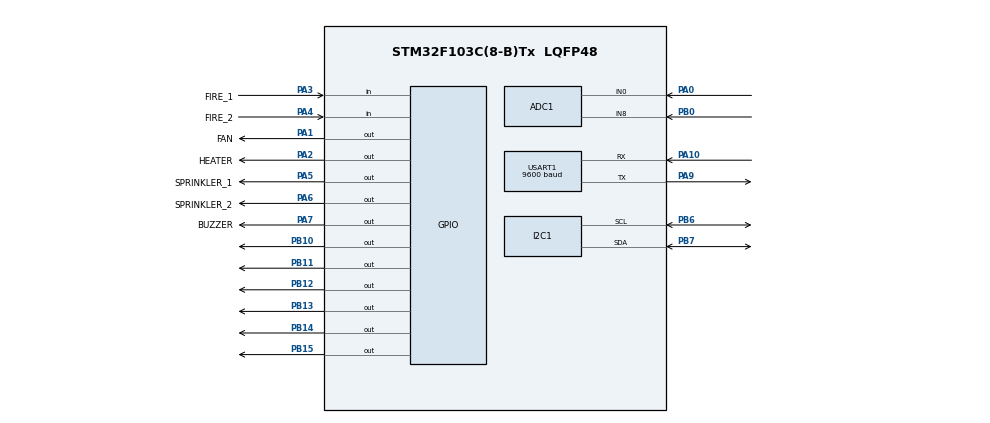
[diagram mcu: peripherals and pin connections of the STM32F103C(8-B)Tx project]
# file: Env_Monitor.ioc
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ADC1.Channel-0\#ChannelRegularConversion=ADC_CHANNEL_0
ADC1.NbrOfConversionFlag=1
ADC1.Rank-0\#ChannelRegularConversion=1
ADC1.SamplingTime-0\#ChannelRegularConversion=ADC_SAMPLETIME_1CYCLE_5
ADC1.master=1
Mcu.Family=STM32F1
Mcu.Name=STM32F103C(8-B)Tx
Mcu.Package=LQFP48
NVIC.PriorityGroup=NVIC_PRIORITYGROUP_4
NVIC.USART1_IRQn=true\:0\:0\:false\:false\:true\:true\:true\:true
PA0-WKUP.Signal=ADCx_IN0
PA1.GPIO_Label=FAN
PA1.Signal=GPIO_Output
PA10.Mode=Asynchronous
PA10.Signal=USART1_RX
PA2.GPIO_Label=HEATER
PA2.Signal=GPIO_Output
PA3.GPIO_Label=FIRE_1
PA3.GPIO_PuPd=GPIO_PULLDOWN
PA3.Signal=GPIO_Input
PA4.GPIO_Label=FIRE_2
PA4.GPIO_PuPd=GPIO_PULLDOWN
PA4.Signal=GPIO_Input
PA5.GPIO_Label=SPRINKLER_1
PA5.Signal=GPIO_Output
PA6.GPIO_Label=SPRINKLER_2
PA6.Signal=GPIO_Output
PA7.GPIO_Label=BUZZER
PA7.Signal=GPIO_Output
PA9.Mode=Asynchronous
PA9.Signal=USART1_TX
PB0.Signal=ADCx_IN8
PB10.Signal=GPIO_Output
PB11.Signal=GPIO_Output
PB12.Signal=GPIO_Output
PB13.Signal=GPIO_Output
PB14.Signal=GPIO_Output
PB15.Signal=GPIO_Output
PB6.Mode=I2C
PB6.Signal=I2C1_SCL
PB7.Mode=I2C
PB7.Signal=I2C1_SDA
ProjectManager.HeapSize=0x200
ProjectManager.StackSize=0x400
ProjectManager.TargetToolchain=STM32CubeIDE
RCC.APB1Freq_Value=8000000
RCC.APB2Freq_Value=8000000
SH.ADCx_IN0.0=ADC1_IN0,IN0
SH.ADCx_IN8.0=ADC1_IN8,IN8
USART1.BaudRate=9600
USART1.VirtualMode=VM_ASYNC
VP_RTC_VS_RTC_Activate.Mode=RTC_Enabled
VP_RTC_VS_RTC_Calendar.Mode=RTC_Calendar
VP_SYS_VS_ND.Mode=No_Debug
board=custom

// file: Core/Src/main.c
/* USER CODE BEGIN Header */
/**
  ******************************************************************************
  * @file           : main.c
  * @brief          : Main program body
  ******************************************************************************
  * @attention
  *
  * Copyright (c) 2026 STMicroelectronics.
  * All rights reserved.
  *
  * This software is licensed under terms that can be found in the LICENSE file
  * in the root directory of this software component.
  * If no LICENSE file comes with this software, it is provided AS-IS.
  *
  ******************************************************************************
  */
/* USER CODE END Header */
#include "main.h"
#include "adc.h"
#include "i2c.h"
#include "rtc.h"
#include "usart.h"
#include "gpio.h"

/* USER CODE BEGIN Includes */
#include "environment.h"
/* USER CODE END Includes */

/* USER CODE BEGIN PD */
//void Stream_System_Telemetry(void) {
//    char tx_packet[256];
//    RTC_TimeTypeDef sTime = {0};
//    RTC_DateTypeDef sDate = {0};
//
//    HAL_RTC_GetTime(&hrtc, &sTime, RTC_FORMAT_BIN);
//    HAL_RTC_GetDate(&hrtc, &sDate, RTC_FORMAT_BIN);
//
//    float cur_t = (total_samples_collected > 0) ? temp_history[(buffer_index == 0 ? MOVING_AVG_SAMPLES : buffer_index) - 1] : 0.0f; // Derived from core history logic
//    float avg_t = Get_Average_Temperature();
//    char fire_msg[15];
//    uint8_t fire_triggered = (HAL_GPIO_ReadPin(GPIOA, GPIO_PIN_3) == GPIO_PIN_SET) ||
//                             (HAL_GPIO_ReadPin(GPIOA, GPIO_PIN_4) == GPIO_PIN_SET);
//
//    snprintf(tx_packet, sizeof(tx_packet),
//             "@TIME=%02d:%02d:%02d|DATE=%02d-%02d-%02d|CUR=%.1f|AVG=%.1f|FIRE=%d|LOCK=%d|TARG=%.1f\n",
//             sTime.Hours, sTime.Minutes, sTime.Seconds,
//             sDate.Year, sDate.Month, sDate.Date,
//             cur_t, avg_t, fire_triggered, is_system_locked, target_temp);
//
//    HAL_UART_Transmit(&huart1, (uint8_t*)tx_packet, strlen(tx_packet), 200);
//}
/* USER CODE END PD */

/* USER CODE BEGIN PV */
extern RTC_HandleTypeDef hrtc;
uint8_t rx_char;
/* USER CODE END PV */

void SystemClock_Config(void);

int main(void)
{

  /* MCU Configuration--------------------------------------------------------*/

  /* Reset of all peripherals, Initializes the Flash interface and the Systick. */
  HAL_Init();

  /* Configure the system clock */
  SystemClock_Config();

  /* Initialize all configured peripherals */
  MX_GPIO_Init();
  MX_ADC1_Init();
  MX_USART1_UART_Init();
  MX_RTC_Init();
  MX_I2C1_Init();
  /* USER CODE BEGIN 2 */
  ENV_Init(&hadc1, &huart1, &hrtc);
  HAL_UART_Receive_IT(&huart1, &rx_char, 1);
  /* USER CODE END 2 */

  /* Infinite loop */
  /* USER CODE BEGIN WHILE */

  uint32_t last_execution_time = 0;
  while (1)
  {
    /* USER CODE END WHILE */

    /* USER CODE BEGIN 3 */
	  uint32_t current_time = HAL_GetTick();
	  if (current_time - last_execution_time >= 1000)
	      {
	          ENV_Task();
	          last_execution_time = current_time;
	      }
	  // Non-Blocking State Machine
//       ENV_Task();
//       HAL_Delay(1500);

  }
  /* USER CODE END 3 */
}

void SystemClock_Config(void)
{
  RCC_OscInitTypeDef RCC_OscInitStruct = {0};
  RCC_ClkInitTypeDef RCC_ClkInitStruct = {0};
  RCC_PeriphCLKInitTypeDef PeriphClkInit = {0};

  /** Initializes the RCC Oscillators according to the specified parameters
  * in the RCC_OscInitTypeDef structure.
  */
  RCC_OscInitStruct.OscillatorType = RCC_OSCILLATORTYPE_HSI|RCC_OSCILLATORTYPE_LSI;
  RCC_OscInitStruct.HSIState = RCC_HSI_ON;
  RCC_OscInitStruct.HSICalibrationValue = RCC_HSICALIBRATION_DEFAULT;
  RCC_OscInitStruct.LSIState = RCC_LSI_ON;
  RCC_OscInitStruct.PLL.PLLState = RCC_PLL_NONE;
  if (HAL_RCC_OscConfig(&RCC_OscInitStruct) != HAL_OK)
  {
    Error_Handler();
  }

  /** Initializes the CPU, AHB and APB buses clocks
  */
  RCC_ClkInitStruct.ClockType = RCC_CLOCKTYPE_HCLK|RCC_CLOCKTYPE_SYSCLK
                              |RCC_CLOCKTYPE_PCLK1|RCC_CLOCKTYPE_PCLK2;
  RCC_ClkInitStruct.SYSCLKSource = RCC_SYSCLKSOURCE_HSI;
  RCC_ClkInitStruct.AHBCLKDivider = RCC_SYSCLK_DIV1;
  RCC_ClkInitStruct.APB1CLKDivider = RCC_HCLK_DIV1;
  RCC_ClkInitStruct.APB2CLKDivider = RCC_HCLK_DIV1;

  if (HAL_RCC_ClockConfig(&RCC_ClkInitStruct, FLASH_LATENCY_0) != HAL_OK)
  {
    Error_Handler();
  }
  PeriphClkInit.PeriphClockSelection = RCC_PERIPHCLK_RTC|RCC_PERIPHCLK_ADC;
  PeriphClkInit.RTCClockSelection = RCC_RTCCLKSOURCE_LSI;
  PeriphClkInit.AdcClockSelection = RCC_ADCPCLK2_DIV2;
  if (HAL_RCCEx_PeriphCLKConfig(&PeriphClkInit) != HAL_OK)
  {
    Error_Handler();
  }
}

/* USER CODE BEGIN 4 */
void HAL_UART_RxCpltCallback(UART_HandleTypeDef *huart) {
    if (huart->Instance == USART1) {
        ENV_ReceiveHandler(rx_char);

        HAL_UART_Receive_IT(&huart1, &rx_char, 1);
    }
}
/* USER CODE END 4 */

void Error_Handler(void)
{
  __disable_irq();
  while (1)
  {
  }
}
